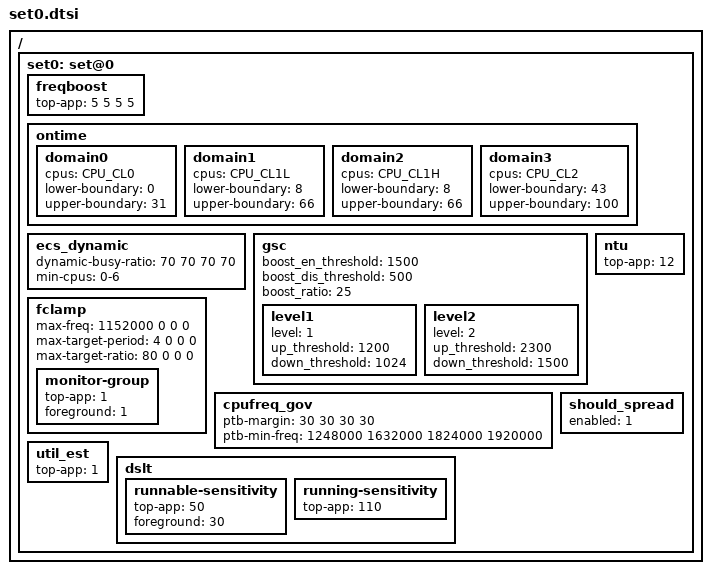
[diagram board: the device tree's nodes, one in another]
/ {
	/* normal mode - default */
	set0: set@0 {
		/* Boosting margin applied to frequency selection */
		freqboost {			/* LIT MED-L MED-H BIG */
			top-app			= < 5  5  5  5 >;
		};

		/* Ontime Migration */
		ontime {
			domain0 {
				cpus = CPU_CL0;
				lower-boundary = <0>;
				upper-boundary = <31>;
			};
			domain1 {
				cpus = CPU_CL1L;
				lower-boundary = <8>;
				upper-boundary = <66>;
			};
			domain2 {
				cpus = CPU_CL1H;
				lower-boundary = <8>;
				upper-boundary = <66>;
			};
			domain3 {
				cpus = CPU_CL2;
				lower-boundary = <43>;
				upper-boundary = <100>;
			};
		};

		ecs_dynamic {
			dynamic-busy-ratio = <70 70 70 70>;
			min-cpus = "0-6";
		};

		gsc {
			boost_en_threshold = <1500>;
			boost_dis_threshold = <500>;
			boost_ratio = <25>;

			level1 {
				level = <1>;
				up_threshold = <1200>;
				down_threshold = <1024>;
			};
			level2 {
				level = <2>;
				up_threshold = <2300>;
				down_threshold = <1500>;
			};
		};

		fclamp {
			max-freq          = < 1152000       0       0       0>;
			max-target-period = <       4       0       0       0>;
			max-target-ratio  = <      80       0       0       0>;

			monitor-group {
				top-app         = <1>;
				foreground      = <1>;
			};
		};

		cpufreq_gov {
				/* LIT MED-L MED-H BIG */
			ptb-margin = < 30 30 30 30 >;
			ptb-min-freq = < 1248000 1632000 1824000 1920000 >;
		};

		ntu {
			top-app			= <12>;
		};

		should_spread {
			enabled = <1>;
		};

		util_est {
			top-app	= <1>;
		};

		dslt {
			runnable-sensitivity {
				top-app    = <50>;
				foreground = <30>;
			};
			running-sensitivity {
				top-app    = <110>;
			};
		};
	};
};
